# STM32U575 register map
File version: 1.4
CPU: CM33 r0p1, little endian, MPU, FPU, 4 interrupt priority bits
Registers are 32-bit, read-write, reset 0x0 unless marked. A register's access mark holds for its fields unless they carry their own. Offsets are from the block's base; [hi:lo] are bit positions; {n}, {i} and the like mark numbered series; 'fields as' and 'values as' point back to an identical list.

## OTFDEC1 — On-The-Fly Decryption engine
Base 0x420C5000
Same registers: OTFDEC2 0x420C5400, SEC_OTFDEC1 0x520C5000, SEC_OTFDEC2 0x520C5400
0x00 CR — OTFDEC control register
  [0] ENC — Encryption mode bit
0x10 PRIVCFGR — OTFDEC privileged access control configuration register
  [0] PRIV — Encryption mode bit
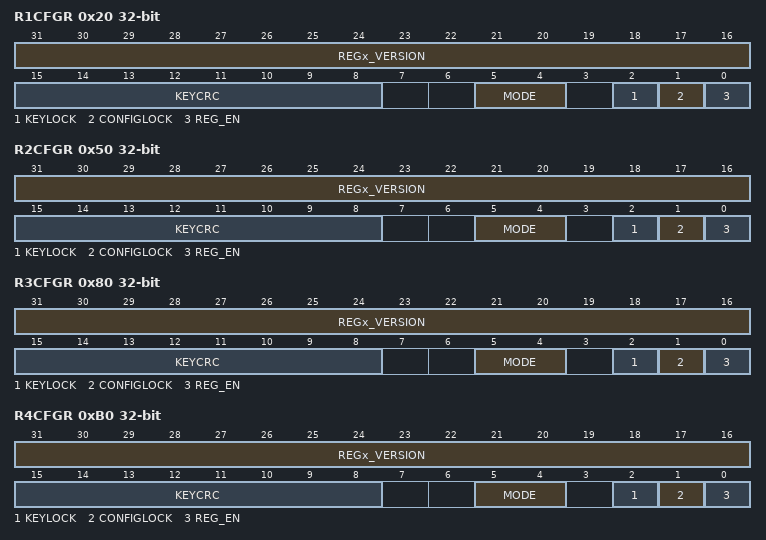
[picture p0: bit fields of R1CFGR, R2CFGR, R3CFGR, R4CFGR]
0x20 R1CFGR access per field — OTFDEC region x configuration register
  [31:16] REGx_VERSION rw — region firmware version
  [15:8] KEYCRC ro — region key 8-bit CRC
  [5:4] MODE rw — operating mode
  [2] KEYLOCK rw — region key lock
  [1] CONFIGLOCK rw — region config lock
  [0] REG_EN rw — region on-the-fly decryption enable
0x24 R1STARTADDR — OTFDEC region x start address register
  [31:0] REGx_START_ADDR — Region AXI start address
0x28 R1ENDADDR reset 0xFFF — OTFDEC region x end address register
  [31:0] REGx_END_ADDR — Region AXI end address
0x2C R1NONCER0 — OTFDEC region x nonce register 0
  [31:0] REGx_NONCE
0x30 R1NONCER1 — OTFDEC region x nonce register 1
  [31:0] REGx_NONCE — Region nonce
{0x4+0x30*i} R{i}KEYR0 wo (i=1..4) — OTFDEC region x key register 0
  [31:0] REGx_KEY
{0x8+0x30*i} R{i}KEYR1 wo (i=1..4) — OTFDEC region x key register 1
  [31:0] REGx_KEY
0x3C R1KEYR2 wo — OTFDEC region x key register 2
  [31:0] REGx_KEY
{0x10+0x30*i} R{i}KEYR3 wo (i=1..4) — OTFDEC region x key register 3
  [31:0] REGx_KEY
0x50 R2CFGR access per field — OTFDEC region x configuration register
  fields as R1CFGR
0x54 R2STARTADDR — OTFDEC region x start address register
  [31:0] REGx_START_ADDR — Region AXI start address
0x58 R2ENDADDR reset 0xFFF — OTFDEC region x end address register
  [31:0] REGx_END_ADDR — Region AXI end address
0x5C R2NONCER0 — OTFDEC region x nonce register 0
  [31:0] REGx_NONCE
0x60 R2NONCER1 — OTFDEC region x nonce register 1
  [31:0] REGx_NONCE — Region nonce, bits [63:32]REGx_NONCE[63:32]
0x6C R2KEYR2 wo — OTFDEC region x key register 2
  [31:0] REGx_KEY_
0x80 R3CFGR access per field — OTFDEC region x configuration register
  fields as R1CFGR
0x84 R3STARTADDR — OTFDEC region x start address register
  [31:0] REGx_START_ADDR — Region AXI start address
0x88 R3ENDADDR reset 0xFFF — OTFDEC region x end address register
  [31:0] REGx_END_ADDR — Region AXI end address
0x8C R4ENDADDR reset 0xFFF — OTFDEC region x end address register
  [31:0] REGx_END_ADDR — Region AXI end address
0x8C R3NONCER0 (alternate view of R4ENDADDR) — OTFDEC region x nonce register 0
  [31:0] REGx_NONCE
0x90 R3NONCER1 — OTFDEC region x nonce register 1
  [31:0] REGx_NONCE
0x9C R3KEYR2 wo — OTFDEC region x key register 2
  [31:0] REGx_KEY
0xB0 R4CFGR access per field — OTFDEC region x configuration register
  fields as R1CFGR
0xB4 R4STARTADDR — OTFDEC region x start address register
  [31:0] REGx_START_ADDR — Region AXI start address
0xBC R4NONCER0 — OTFDEC region x nonce register 0
  [31:0] REGx_NONCE
0xC0 R4NONCER1 — OTFDEC region x nonce register 1
  [31:0] REGx_NONCE
0xCC R4KEYR2 wo — OTFDEC region x key register 2
  [31:0] REGx_KEY
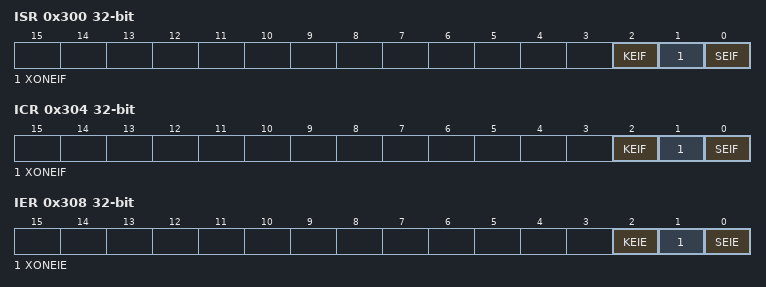
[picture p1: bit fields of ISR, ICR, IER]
0x300 ISR ro — OTFDEC interrupt status register
  [2] KEIF — Key Error Interrupt Flag status
  [1] XONEIF — Execute-only execute-Never Error Interrupt Flag status
  [0] SEIF — Security Error Interrupt Flag status
0x304 ICR ro — OTFDEC interrupt clear register
  [2] KEIF
  [1] XONEIF — Execute-only execute-Never Error Interrupt Flag clear
  [0] SEIF
0x308 IER — OTFDEC interrupt enable register
  [2] KEIE
  [1] XONEIE
  [0] SEIE — Security Error Interrupt Enable

## RAMCFG
Base 0x40026000
Same registers: SEC_RAMCFG 0x50026000
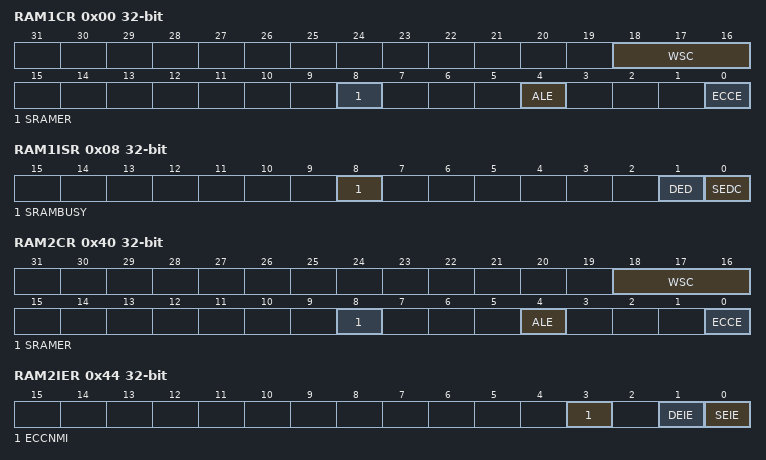
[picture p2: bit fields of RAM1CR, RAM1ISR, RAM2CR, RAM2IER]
0x00 RAM1CR — RAMCFG SRAM x control register
  [18:16] WSC, [8] SRAMER, [4] ALE, [0] ECCE
0x08 RAM1ISR ro — RAMCFG RAMx interrupt status register
  [8] SRAMBUSY, [1] DED, [0] SEDC
0x28 RAM1ERKEYR wo — RAMCFG SRAM x erase key register
  [7:0] ERASEKEY
0x40 RAM2CR — RAMCFG SRAM x control register
  [18:16] WSC, [8] SRAMER, [4] ALE, [0] ECCE
0x44 RAM2IER — RAMCFG SRAM x interrupt enable register
  [3] ECCNMI, [1] DEIE, [0] SEIE
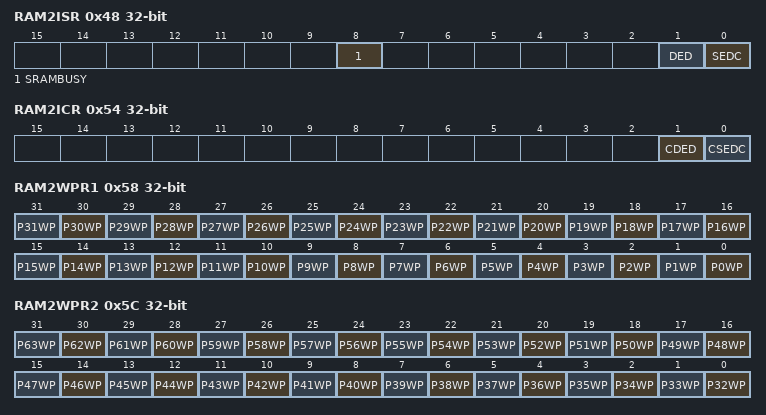
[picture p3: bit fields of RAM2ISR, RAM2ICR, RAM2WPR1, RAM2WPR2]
0x48 RAM2ISR ro — RAMCFG RAMx interrupt status register
  [8] SRAMBUSY, [1] DED, [0] SEDC
0x4C RAM2SEAR ro — RAMCFG RAM x ECC single error address register
  [31:0] ESEA
0x50 RAM2DEAR ro — RAMCFG RAM x ECC double error address register
  [31:0] EDEA
0x54 RAM2ICR — RAMCFG RAM x interrupt clear register x
  [1] CDED, [0] CSEDC
0x58 RAM2WPR1 — RAMCFG SRAM2 write protection register 1
  [n] P{n}WP (n=0..31)
0x5C RAM2WPR2 — RAMCFG SRAM2 write protection register 2
  [n-32] P{n}WP (n=32..63)
0x64 RAM2ECCKEYR wo — RAMCFG SRAM x ECC key register
  [7:0] ECCKEY
0x68 RAM2ERKEYR wo — RAMCFG SRAM x erase key register
  [7:0] ERASEKEY
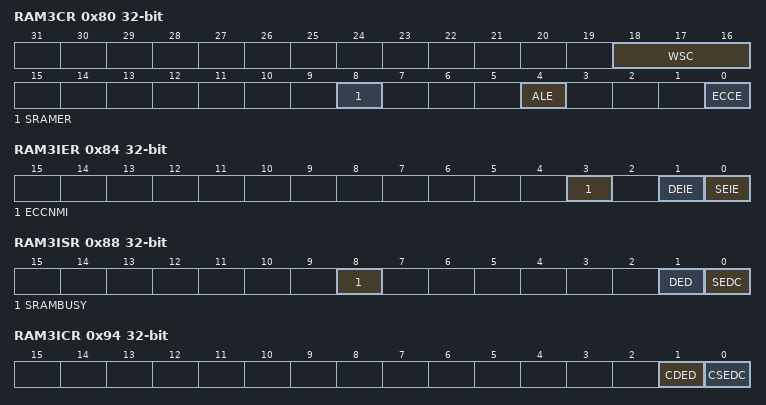
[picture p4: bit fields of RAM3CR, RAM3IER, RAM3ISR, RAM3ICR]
0x80 RAM3CR — RAMCFG SRAM x control register
  [18:16] WSC, [8] SRAMER, [4] ALE, [0] ECCE
0x84 RAM3IER — RAMCFG SRAM x interrupt enable register
  [3] ECCNMI, [1] DEIE, [0] SEIE
0x88 RAM3ISR ro — RAMCFG RAMx interrupt status register
  [8] SRAMBUSY, [1] DED, [0] SEDC
0x8C RAM3SEAR ro — RAMCFG RAM x ECC single error address register
  [31:0] ESEA
0x90 RAM3DEAR ro — RAMCFG RAM x ECC double error address register
  [31:0] EDEA
0x94 RAM3ICR — RAMCFG RAM x interrupt clear register x
  [1] CDED, [0] CSEDC
0xA4 RAM3ECCKEYR wo — RAMCFG SRAM x ECC key register
  [7:0] ECCKEY
0xA8 RAM3ERKEYR wo — RAMCFG SRAM x erase key register
  [7:0] ERASEKEY
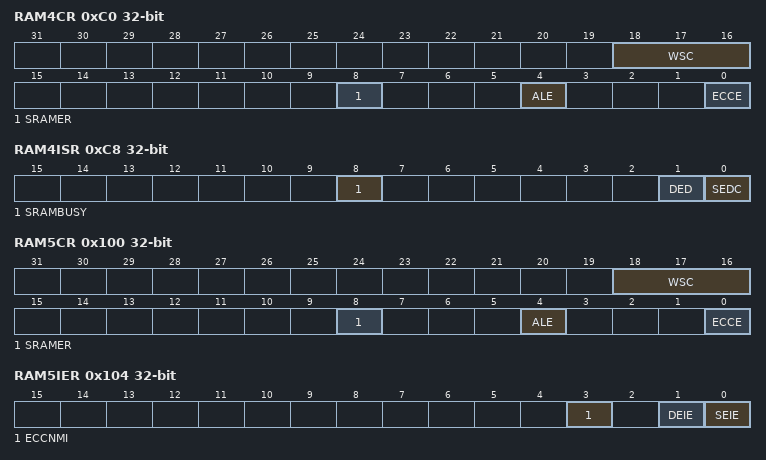
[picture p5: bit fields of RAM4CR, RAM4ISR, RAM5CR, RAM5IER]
0xC0 RAM4CR — RAMCFG SRAM x control register
  [18:16] WSC, [8] SRAMER, [4] ALE, [0] ECCE
0xC8 RAM4ISR ro — RAMCFG RAMx interrupt status register
  [8] SRAMBUSY, [1] DED, [0] SEDC
0xE8 RAM4ERKEYR wo — RAMCFG SRAM x erase key register
  [7:0] ERASEKEY
0x100 RAM5CR — RAMCFG SRAM x control register
  [18:16] WSC, [8] SRAMER, [4] ALE, [0] ECCE
0x104 RAM5IER — RAMCFG SRAM x interrupt enable register
  [3] ECCNMI, [1] DEIE, [0] SEIE
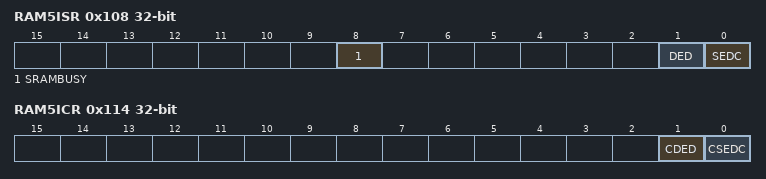
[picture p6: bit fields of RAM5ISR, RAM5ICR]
0x108 RAM5ISR ro — RAMCFG RAMx interrupt status register
  [8] SRAMBUSY, [1] DED, [0] SEDC
0x10C RAM5SEAR ro — RAMCFG RAM x ECC single error address register
  [31:0] ESEA
0x110 RAM5DEAR ro — RAMCFG RAM x ECC double error address register
  [31:0] EDEA
0x114 RAM5ICR — RAMCFG RAM x interrupt clear register x
  [1] CDED, [0] CSEDC

## DCMI — Digital camera interface
Base 0x4202C000
Same registers: SEC_DCMI 0x5202C000
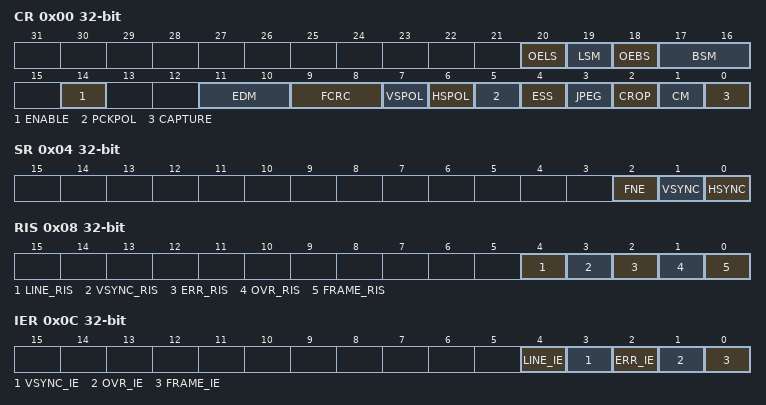
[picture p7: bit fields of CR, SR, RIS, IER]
0x00 CR — control register
  [20] OELS — Odd/Even Line Select (Line Select Start)
  [19] LSM — Line Select mode
  [18] OEBS — Odd/Even Byte Select (Byte Select Start)
  [17:16] BSM — Byte Select mode
  [14] ENABLE — DCMI enable
  [11:10] EDM — Extended data mode
  [9:8] FCRC — Frame capture rate control
  [7] VSPOL — Vertical synchronization polarity
  [6] HSPOL — Horizontal synchronization polarity
  [5] PCKPOL — Pixel clock polarity
  [4] ESS — Embedded synchronization select
  [3] JPEG — JPEG format
  [2] CROP — Crop feature
  [1] CM — Capture mode
  [0] CAPTURE — Capture enable
0x04 SR ro — status register
  [2] FNE — FIFO not empty
  [1] VSYNC — Vertical synchronization
  [0] HSYNC — Horizontal synchronization
0x08 RIS ro — raw interrupt status register
  [4] LINE_RIS — Line raw interrupt status
  [3] VSYNC_RIS — DCMI_VSYNC raw interrupt status
  [2] ERR_RIS — Synchronization error raw interrupt status
  [1] OVR_RIS — Overrun raw interrupt status
  [0] FRAME_RIS — Capture complete raw interrupt status
0x0C IER — interrupt enable register
  [4] LINE_IE — Line interrupt enable
  [3] VSYNC_IE — DCMI_VSYNC interrupt enable
  [2] ERR_IE — Synchronization error interrupt enable
  [1] OVR_IE — Overrun interrupt enable
  [0] FRAME_IE — Capture complete interrupt enable
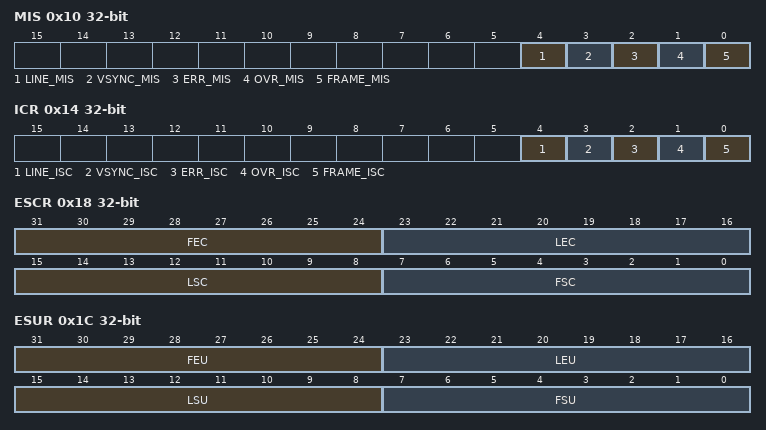
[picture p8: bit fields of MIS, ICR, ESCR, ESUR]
0x10 MIS ro — masked interrupt status register
  [4] LINE_MIS — Line masked interrupt status
  [3] VSYNC_MIS — VSYNC masked interrupt status
  [2] ERR_MIS — Synchronization error masked interrupt status
  [1] OVR_MIS — Overrun masked interrupt status
  [0] FRAME_MIS — Capture complete masked interrupt status
0x14 ICR wo — interrupt clear register
  [4] LINE_ISC — line interrupt status clear
  [3] VSYNC_ISC — Vertical Synchronization interrupt status clear
  [2] ERR_ISC — Synchronization error interrupt status clear
  [1] OVR_ISC — Overrun interrupt status clear
  [0] FRAME_ISC — Capture complete interrupt status clear
0x18 ESCR — background offset register
  [31:24] FEC — Frame end delimiter code
  [23:16] LEC — Line end delimiter code
  [15:8] LSC — Line start delimiter code
  [7:0] FSC — Frame start delimiter code
0x1C ESUR — embedded synchronization unmask register
  [31:24] FEU — Frame end delimiter unmask
  [23:16] LEU — Line end delimiter unmask
  [15:8] LSU — Line start delimiter unmask
  [7:0] FSU — Frame start delimiter unmask
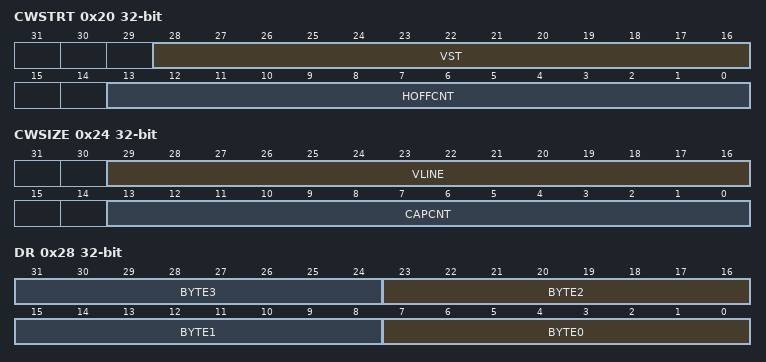
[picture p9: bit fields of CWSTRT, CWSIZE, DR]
0x20 CWSTRT — crop window start
  [28:16] VST — Vertical start line count
  [13:0] HOFFCNT — Horizontal offset count
0x24 CWSIZE — crop window size
  [29:16] VLINE — Vertical line count
  [13:0] CAPCNT — Capture count
0x28 DR ro — data register
  [8n+7:8n] BYTE{n} (n=0..3) — Data byte {n}

## DCB — Debug Control Block
Base 0xE000EE08
0x00 DSCSR — Debug Security Control and Status Register
  [16] CDS — Current domain Secure
